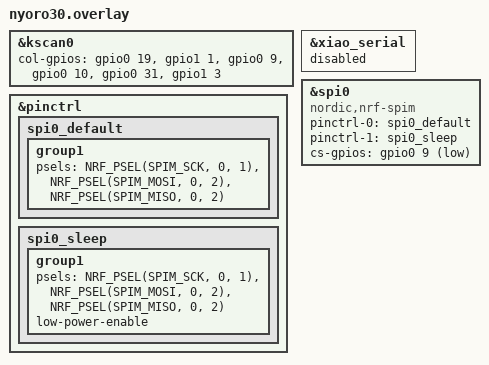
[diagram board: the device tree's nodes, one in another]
#include "nyoro30.dtsi"

&kscan0 {
        col-gpios
            = <&gpio0 19  GPIO_ACTIVE_HIGH>
            , <&gpio1  1  GPIO_ACTIVE_HIGH> 
            , <&gpio0  9  GPIO_ACTIVE_HIGH> 
            , <&gpio0 10  GPIO_ACTIVE_HIGH>
            , <&gpio0 31  GPIO_ACTIVE_HIGH> 
            , <&gpio1  3  GPIO_ACTIVE_HIGH> 
            ;
};

&pinctrl {
    spi0_default: spi0_default {
        group1 {
            psels = <NRF_PSEL(SPIM_SCK, 0, 1)>,
                <NRF_PSEL(SPIM_MOSI, 0, 2)>,
                <NRF_PSEL(SPIM_MISO, 0, 2)>;
        };
    };

    spi0_sleep: spi0_sleep {
        group1 {
            psels = <NRF_PSEL(SPIM_SCK, 0, 1)>,
                <NRF_PSEL(SPIM_MOSI, 0, 2)>,
                <NRF_PSEL(SPIM_MISO, 0, 2)>;
            low-power-enable;
        };
    };
};

&xiao_serial { status = "disabled"; };

&spi0 {
    status = "okay";
    compatible = "nordic,nrf-spim";
    pinctrl-0 = <&spi0_default>;
    pinctrl-1 = <&spi0_sleep>;
    pinctrl-names = "default", "sleep";
    cs-gpios = <&gpio0 9 GPIO_ACTIVE_LOW>;
};
